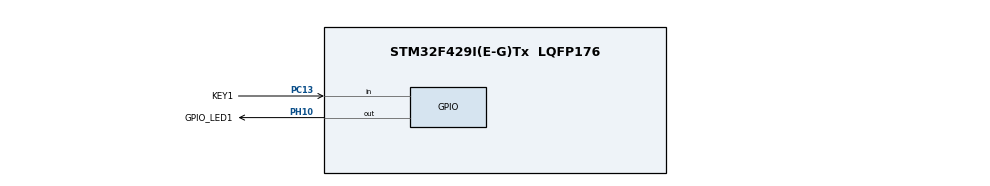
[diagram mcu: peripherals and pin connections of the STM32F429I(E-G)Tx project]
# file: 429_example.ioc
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Mcu.Family=STM32F4
Mcu.Name=STM32F429I(E-G)Tx
Mcu.Package=LQFP176
NVIC.PriorityGroup=NVIC_PRIORITYGROUP_4
PA0/WKUP.Mode=SYS_WakeUp0
PA0/WKUP.Signal=SYS_WKUP
PA13.Mode=Serial_Wire
PA13.Signal=SYS_JTMS-SWDIO
PA14.Mode=Serial_Wire
PA14.Signal=SYS_JTCK-SWCLK
PC13.GPIO_Label=KEY1
PC13.GPIO_PuPd=GPIO_PULLDOWN
PC13.Signal=GPIO_Input
PC14/OSC32_IN.Mode=LSE-External-Oscillator
PC14/OSC32_IN.Signal=RCC_OSC32_IN
PC15/OSC32_OUT.Mode=LSE-External-Oscillator
PC15/OSC32_OUT.Signal=RCC_OSC32_OUT
PH0/OSC_IN.Mode=HSE-External-Oscillator
PH0/OSC_IN.Signal=RCC_OSC_IN
PH1/OSC_OUT.Mode=HSE-External-Oscillator
PH1/OSC_OUT.Signal=RCC_OSC_OUT
PH10.GPIO_Label=GPIO_LED1
PH10.GPIO_PuPd=GPIO_NOPULL
PH10.Signal=GPIO_Output
ProjectManager.HeapSize=0x200
ProjectManager.StackSize=0x400
ProjectManager.TargetToolchain=MDK-ARM V5
RCC.48MHZClocksFreq_Value=40000000
RCC.AHBFreq_Value=80000000
RCC.APB1CLKDivider=RCC_HCLK_DIV2
RCC.APB1Freq_Value=40000000
RCC.APB1TimFreq_Value=80000000
RCC.APB2Freq_Value=80000000
RCC.APB2TimFreq_Value=80000000
RCC.CortexFreq_Value=80000000
RCC.HCLKFreq_Value=80000000
RCC.HSE_VALUE=25000000
RCC.HSI_VALUE=16000000
RCC.PLLM=8
RCC.PLLN=80
RCC.SYSCLKFreq_VALUE=80000000
RCC.SYSCLKSource=RCC_SYSCLKSOURCE_PLLCLK
RCC.VCOOutputFreq_Value=160000000
board=custom

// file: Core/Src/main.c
/* USER CODE BEGIN Header */
/**
  ******************************************************************************
  * @file           : main.c
  * @brief          : Main program body
  ******************************************************************************
  * @attention
  *
  * <h2><center>&copy; Copyright (c) 2022 STMicroelectronics.
  * All rights reserved.</center></h2>
  *
  * This software component is licensed by ST under BSD 3-Clause license,
  * the "License"; You may not use this file except in compliance with the
  * License. You may obtain a copy of the License at:
  *                        opensource.org/licenses/BSD-3-Clause
  *
  ******************************************************************************
  */
/* USER CODE END Header */
#include "main.h"
#include "gpio.h"

/* USER CODE BEGIN PTD */
uint16_t Key_Scan(GPIO_TypeDef* GPIOx, uint16_t GPIO_PIN)
{
	if(LL_GPIO_IsInputPinSet(GPIOx,GPIO_PIN) == 1)
	{
		while(LL_GPIO_IsInputPinSet(GPIOx,GPIO_PIN) == 1);

		return 1;
	}
	else
		return 0;
}
/* USER CODE END PTD */

void SystemClock_Config(void);

int main(void)
{

  /* MCU Configuration--------------------------------------------------------*/

  /* Reset of all peripherals, Initializes the Flash interface and the Systick. */

  LL_APB2_GRP1_EnableClock(LL_APB2_GRP1_PERIPH_SYSCFG);
  LL_APB1_GRP1_EnableClock(LL_APB1_GRP1_PERIPH_PWR);

  NVIC_SetPriorityGrouping(NVIC_PRIORITYGROUP_4);

  /* System interrupt init*/
  /* SysTick_IRQn interrupt configuration */
  NVIC_SetPriority(SysTick_IRQn, NVIC_EncodePriority(NVIC_GetPriorityGrouping(),15, 0));

  /* Configure the system clock */
  SystemClock_Config();

  /* Initialize all configured peripherals */
  MX_GPIO_Init();

  /* Infinite loop */
  while (1)
  {

    /* USER CODE BEGIN 3 */
		if(Key_Scan(KEY1_GPIO_Port,KEY1_Pin))
		{

			LL_GPIO_TogglePin(GPIO_LED1_GPIO_Port,GPIO_LED1_Pin);

		}
		//LL_mDelay(100);
		//LL_GPIO_ResetOutputPin(GPIO_LED1_GPIO_Port,GPIO_LED1_Pin);
  }
  /* USER CODE END 3 */
}

void SystemClock_Config(void)
{
  LL_FLASH_SetLatency(LL_FLASH_LATENCY_2);
  while(LL_FLASH_GetLatency()!= LL_FLASH_LATENCY_2)
  {
  }
  LL_PWR_SetRegulVoltageScaling(LL_PWR_REGU_VOLTAGE_SCALE3);
  LL_PWR_DisableOverDriveMode();
  LL_RCC_HSI_SetCalibTrimming(16);
  LL_RCC_HSI_Enable();

   /* Wait till HSI is ready */
  while(LL_RCC_HSI_IsReady() != 1)
  {

  }
  LL_RCC_PLL_ConfigDomain_SYS(LL_RCC_PLLSOURCE_HSI, LL_RCC_PLLM_DIV_8, 80, LL_RCC_PLLP_DIV_2);
  LL_RCC_PLL_Enable();

   /* Wait till PLL is ready */
  while(LL_RCC_PLL_IsReady() != 1)
  {

  }
  LL_RCC_SetAHBPrescaler(LL_RCC_SYSCLK_DIV_1);
  LL_RCC_SetAPB1Prescaler(LL_RCC_APB1_DIV_2);
  LL_RCC_SetAPB2Prescaler(LL_RCC_APB2_DIV_1);
  LL_RCC_SetSysClkSource(LL_RCC_SYS_CLKSOURCE_PLL);

   /* Wait till System clock is ready */
  while(LL_RCC_GetSysClkSource() != LL_RCC_SYS_CLKSOURCE_STATUS_PLL)
  {

  }
  LL_Init1msTick(80000000);
  LL_SetSystemCoreClock(80000000);
  LL_RCC_SetTIMPrescaler(LL_RCC_TIM_PRESCALER_TWICE);
}

void Error_Handler(void)
{
  __disable_irq();
  while (1)
  {
  }
}

/************************ (C) COPYRIGHT STMicroelectronics *****END OF FILE****/
